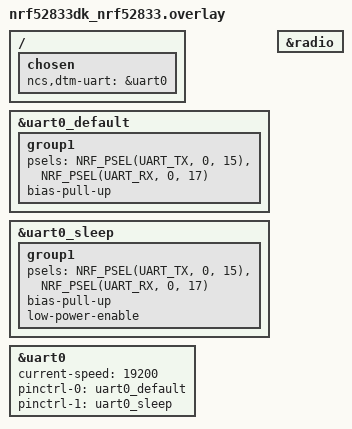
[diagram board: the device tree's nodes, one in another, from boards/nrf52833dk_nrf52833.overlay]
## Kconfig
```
#
# Copyright (c) 2020 Nordic Semiconductor
#
# SPDX-License-Identifier: LicenseRef-Nordic-5-Clause
#

mainmenu "Nordic DTM sample"

# --- 추가된 부분: prj.conf의 설정을 인식시키기 위한 애플리케이션 심볼 ---
config BT_DTM_APP
	bool "Enable DTM Application Logic"
	default y
	select BT_CTLR_DTM if BT_CTLR
	select BT_CTLR_DTM_UART if BT_CTLR
	help
	  This symbol enables the DTM application logic and selects 
	  necessary controller-level DTM symbols.

# ---------------------------------------------------------

config DTM_RADIO_IRQ_PRIORITY
	int "Radio interrupt priority"
	range 0 5 if ZERO_LATENCY_IRQS
	range 0 6
	default 2
	help
	  Sets Radio interrupt priority.
	  Levels are from 0 (highest priority) to 6 (lowest priority)

config DTM_TIMER_IRQ_PRIORITY
	int "DTM timer interrupt priority"
	range 0 5 if ZERO_LATENCY_IRQS
	range 0 6
	default 3
	help
	  Sets DTM timer interrupt priority.
	  Levels are from 0 (highest priority) to 6 (lowest priority)

config ANOMALY_172_TIMER_IRQ_PRIORITY
	int "Anomaly 172 timer interrupt priority"
	depends on SOC_NRF52840
	range 0 5 if ZERO_LATENCY_IRQS
	range 0 6
	default 2
	help
	  Sets anomaly 172 timer interrupt priority.
	  Levels are from 0 (highest priority) to 6 (lowest priority)

config DTM_USB
	bool "DTM over USB CDC ACM class"
	depends on SOC_NRF5340_CPUNET && !DTM_TRANSPORT_HCI
	select EXPERIMENTAL
	help
	  Use USB instead of UART as the DTM interface. For nRF5340 the USB from application core
	  is used as communication interface.

config DTM_TRANSPORT_HCI
	bool "DTM over HCI UART [EXPERIMENTAL]"
	depends on SERIAL
	depends on NET_BUF
	select EXPERIMENTAL
	help
	  Use the HCI UART transport interface as the DTM transport layer.
	  This option is inherited from SB_CONFIG_DTM_TRANSPORT_HCI.

if DTM_TRANSPORT_HCI

config DTM_HCI_QUEUE_COUNT
	int "Count of HCI RX/TX queues"
	default 16
	help
	  Maximum depth of the HCI RX/TX queues.

config DTM_HCI_QUEUE_SIZE
	int "Size of HCI RX/TX queue buffer"
	default 1024
	help
	  Maximum size of the HCI RX/TX queue element.

config DTM_HCI_TX_THREAD_STACK_SIZE
	int "Stack size of TX thread"
	default 2048
	help
	  Stack size of the TX thread.

config DTM_HCI_TX_THREAD_PRIORITY
	int "TX thread priority"
	default 7
	help
	  Priority of the TX thread.

endif # DTM_TRANSPORT_HCI

config DTM_POWER_CONTROL_AUTOMATIC
	bool "Automatic power control"
	depends on FEM
	default y
	help
	  Set the SoC output power and the front-end module gain to achieve the TX output power
	  requested by user. If the exact value cannot be achieved, power is set to the closest
	  possible value. If this option is disabled, user can set the SoC output power and the
	  front-end module gain with the separate vendor specific commands.

config DTM_FAST_RAMP_UP
	bool "Enable radio fast ramp up mode"
	default y
	help
	  Do fast ramp up when starting the radio peripheral. This mode will significancy reduce
	  the ramp up time and makes it almost the same on all supported chips.

module = DTM_TRANSPORT
module-str = "DTM_transport"
source "${ZEPHYR_BASE}/subsys/logging/Kconfig.template.log_config"

source "Kconfig.zephyr"
```

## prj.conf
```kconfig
# Bluetooth & Controller
CONFIG_BT=y
CONFIG_BT_CTLR=y

# DTM 애플리케이션 활성화 (위에서 추가한 Kconfig 심볼 사용)
CONFIG_BT_DTM_APP=y

# DTM sample dependencies
CONFIG_NRFX_TIMER0=y
CONFIG_NRFX_TIMER1=y
CONFIG_NRFX_TIMER2=y
CONFIG_NRFX_GPPI=y
CONFIG_CLOCK_CONTROL=y

# NFC 핀(P0.09) GPIO로 해제 (v3.1.0 권장 심볼)
CONFIG_NFCT_PINS_AS_GPIOS=y

# 안테나 게인 보정 (0dBm)
CONFIG_BT_CTLR_TX_PWR_ANTENNA=0

# UART 설정
CONFIG_SERIAL=y
CONFIG_UART_INTERRUPT_DRIVEN=y
# HWFC는 Overlay 파일에서 제거

# 로그 및 콘솔 비활성화 (DTM 바이너리 통신 간섭 방지)
CONFIG_CONSOLE=y
CONFIG_UART_CONSOLE=n
CONFIG_LOG=n
CONFIG_NCS_BOOT_BANNER=n
CONFIG_BOOT_BANNER=n
CONFIG_EARLY_CONSOLE=n
CONFIG_PRINTK=n

# 시스템 클럭 (HFXO 사용)
CONFIG_CLOCK_CONTROL_NRF_K32SRC_XTAL=y
CONFIG_CLOCK_CONTROL_NRF_K32SRC_20PPM=y
```

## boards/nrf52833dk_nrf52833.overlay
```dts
/ {
    chosen {
        /* DTM 제어용 UART를 uart0(P0.15/P0.17)로 지정 */
        ncs,dtm-uart = &uart0;
    };
};

&uart0_default {
    /* Keep only TX/RX mapping used by DTM on P0.15/P0.17. */
    /delete-node/ group2;

    group1 {
        psels = <NRF_PSEL(UART_TX, 0, 15)>,
                <NRF_PSEL(UART_RX, 0, 17)>;
        bias-pull-up;
    };
};

&uart0_sleep {
    group1 {
        psels = <NRF_PSEL(UART_TX, 0, 15)>,
                <NRF_PSEL(UART_RX, 0, 17)>;
        bias-pull-up;
        low-power-enable;
    };
};

&uart0 {
    status = "okay";
    current-speed = <19200>;
    /delete-property/ hw-flow-control;
    pinctrl-0 = <&uart0_default>;
    pinctrl-1 = <&uart0_sleep>;
    pinctrl-names = "default", "sleep";
};

&radio {
    /* Disable Direction Finding for this board build (no DFE GPIO map configured). */
    /delete-property/ dfe-supported;
};
```

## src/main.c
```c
/*
 * Copyright (c) 2020 Nordic Semiconductor ASA
 *
 * SPDX-License-Identifier: LicenseRef-Nordic-5-Clause
 */

#include <zephyr/device.h>

#include "transport/dtm_transport.h"

int main(void)
{
	int err;
	union dtm_tr_packet cmd;

	err = dtm_tr_init();
	if (err) {
		return err;
	}

	for (;;) {
		cmd = dtm_tr_get();
		err = dtm_tr_process(cmd);
		if (err) {
			return err;
		}
	}
}
```
